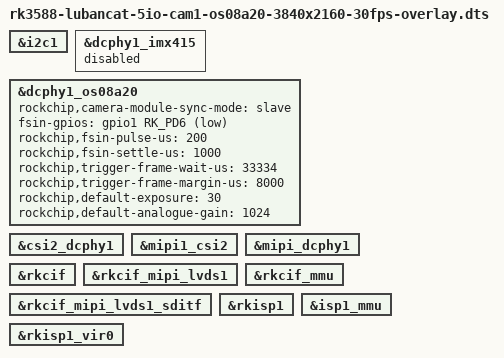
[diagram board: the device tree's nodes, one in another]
/dts-v1/;
/plugin/;

#include <dt-bindings/usb/pd.h>
#include <dt-bindings/gpio/gpio.h>
#include <dt-bindings/pwm/pwm.h>
#include <dt-bindings/pinctrl/rockchip.h>
#include <dt-bindings/input/rk-input.h>
#include <dt-bindings/display/drm_mipi_dsi.h>
#include <dt-bindings/display/rockchip_vop.h>
#include <dt-bindings/sensor-dev.h>

/ {
/* Link path: sensor->csi2_dphy1->mipi2_csi2->rkcif_mipi_lvds2--->rkcif_mipi_lvds2_sditf->rkisp0_vir2 */
	fragment@0 {
		target = <&i2c1>;
		__overlay__ {
			status = "okay";
		};
	};

	/* Disable imx415 when using os08a20 - only one sensor per cam slot */
	fragment@1 {
		target = <&dcphy1_imx415>;
		__overlay__ {
			status = "disabled";
		};
	};

	fragment@2 {
		target = <&dcphy1_os08a20>;
		__overlay__ {
			status = "okay";
			/* External single-frame trigger via FSIN pin */
			rockchip,camera-module-sync-mode = "slave";
			/* FSIN is wired to GPIO1_D6 (RK_PD6) */
			fsin-gpios = <&gpio1 RK_PD6 GPIO_ACTIVE_LOW>;
			/* 如需临时调试，可改为其它 GPIO，例如： */
			//fsin-gpios = <&gpio0 RK_PC6 GPIO_ACTIVE_LOW>;

			/* Pulse width in microseconds (logical active time) */
			rockchip,fsin-pulse-us = <200>;
			/* 低延迟触发时序参数（单位：us） */
			rockchip,fsin-settle-us = <1000>;
			/* 最短安全等待：约1帧@30fps */
			rockchip,trigger-frame-wait-us = <33334>;
			/* 额外安全边际：减小“偶发切半帧/丢帧”概率 */
			rockchip,trigger-frame-margin-us = <8000>;
			/* 触发间隔完全由外部输入控制 */
			/* 默认曝光行数，用于 V4L2 曝光控件初始值（单位：行） */
			rockchip,default-exposure = <30>;
			/* 默认模拟增益，1024=1.0x，用于 V4L2 增益控件初始值 */
			rockchip,default-analogue-gain = <1024>;
		};
	};

	fragment@3 {
		target = <&csi2_dcphy1>;

		__overlay__ {
			status = "okay";
		};
	};

	fragment@4 {
		target = <&mipi1_csi2>;

		__overlay__ {
			status = "okay";
		};
	};

	fragment@5 {
		target = <&mipi_dcphy1>;

		__overlay__ {
			status = "okay";
		};
	};

	fragment@6 {
		target = <&rkcif>;

		__overlay__ {
			status = "okay";
		};
	};

	fragment@7 {
		target = <&rkcif_mipi_lvds1>;

		__overlay__ {
			status = "okay";
		};
	};

	fragment@8 {
		target = <&rkcif_mipi_lvds1_sditf>;

		__overlay__ {
			status = "okay";
		};
	};

	fragment@9 {
		target = <&rkcif_mmu>;

		__overlay__ {
			status = "okay";
		};
	};

	fragment@10 {
		target = <&rkisp1>;

		__overlay__ {
			status = "okay";
		};
	};

	fragment@11 {
		target = <&isp1_mmu>;

		__overlay__ {
			status = "okay";
		};
	};

	fragment@12 {
		target = <&rkisp1_vir0>;

		__overlay__ {
			status = "okay";
		};
	};
};

